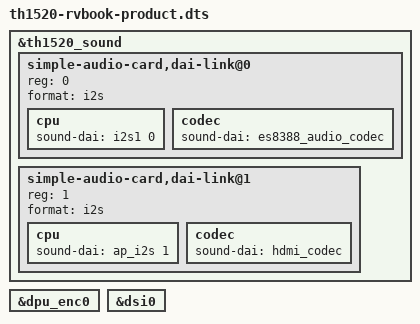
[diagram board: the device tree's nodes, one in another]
/* SPDX-License-Identifier: GPL-2.0 */	
/*
 * Copyright (C) 2021 Alibaba Group Holding Limited.
 */

/dts-v1/;

#include "th1520-rvbook-dsi0.dts"

&th1520_sound {
        status = "okay";
        simple-audio-card,dai-link@0 {          /* I2S - AUDIO SYS CODEC 8388*/
                reg = <0>;
                format = "i2s";
                cpu {
                        sound-dai = <&i2s1 0>;
                };
                codec {
                        sound-dai = <&es8388_audio_codec>;
                };
        };
        simple-audio-card,dai-link@1 {          /* I2S - HDMI*/
                reg = <1>;
                format = "i2s";
                cpu {
                        sound-dai = <&ap_i2s 1>;
                };
                codec {
                        sound-dai = <&hdmi_codec>;
                };
        };
};

&dpu_enc0 {
        status = "okay";
};

&dsi0 {
        status = "okay";
};
